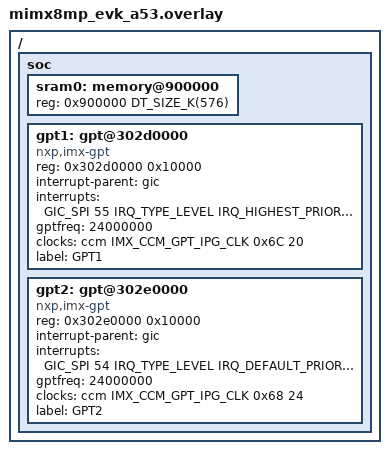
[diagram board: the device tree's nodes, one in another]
#define IRQ_HIGHEST_PRIORITY	0
/ {
	soc {
		/delete-node/ memory@c0000000;

		sram0: memory@900000 {
			reg = <0x900000 DT_SIZE_K(576)>;
		};

		gpt1: gpt@302d0000 {
			compatible = "nxp,imx-gpt";
			reg = <0x302d0000 0x10000>;
			interrupt-parent = <&gic>;
			interrupts = <GIC_SPI 55 IRQ_TYPE_LEVEL
				IRQ_HIGHEST_PRIORITY>;
			gptfreq = <24000000>;
			clocks = <&ccm IMX_CCM_GPT_IPG_CLK 0x6C 20>;
			label = "GPT1";
		};

		gpt2: gpt@302e0000 {
			compatible = "nxp,imx-gpt";
			reg = <0x302e0000 0x10000>;
			interrupt-parent = <&gic>;
			interrupts = <GIC_SPI 54 IRQ_TYPE_LEVEL
				IRQ_DEFAULT_PRIORITY>;
			gptfreq = <24000000>;
			clocks = <&ccm IMX_CCM_GPT_IPG_CLK 0x68 24>;
			label = "GPT2";
		};
	};
};
